# MSP430FR5739 register map
File version: 1.1
CPU: msp430
Registers are 16-bit, access not given, reset 0x0 unless marked. A register's access mark holds for its fields unless they carry their own. Offsets are from the block's base; [hi:lo] are bit positions; {n}, {i} and the like mark numbered series.

## SFR__Special_Function_Registers
Base 0x00000000
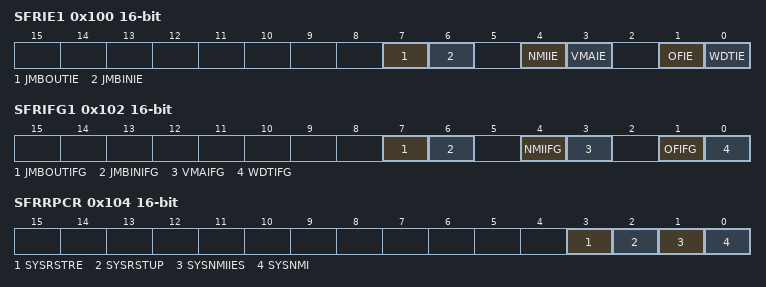
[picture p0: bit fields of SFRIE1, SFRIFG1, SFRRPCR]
0x100 SFRIE1 — Interrupt Enable 1
  [7] JMBOUTIE — [7:7] JTAG Mail Box output Interrupt Enable
  [6] JMBINIE — [6:6] JTAG Mail Box input Interrupt Enable
  [4] NMIIE — [4:4] NMI Interrupt Enable
  [3] VMAIE — [3:3] Vacant Memory Interrupt Enable
  [1] OFIE — [1:1] Osc Fault Enable
  [0] WDTIE — [0:0] WDT Interrupt Enable
0x102 SFRIFG1 — Interrupt Flag 1
  [7] JMBOUTIFG — [7:7] JTAG Mail Box output Interrupt Flag
  [6] JMBINIFG — [6:6] JTAG Mail Box input Interrupt Flag
  [4] NMIIFG — [4:4] NMI Interrupt Flag
  [3] VMAIFG — [3:3] Vacant Memory Interrupt Flag
  [1] OFIFG — [1:1] Osc Fault Flag
  [0] WDTIFG — [0:0] WDT Interrupt Flag
0x104 SFRRPCR — RESET Pin Control Register
  [3] SYSRSTRE — [3:3] RESET Pin Resistor enable
  [2] SYSRSTUP — [2:2] RESET Pin pull down/up select
  [1] SYSNMIIES — [1:1] NMI edge select
  [0] SYSNMI — [0:0] NMI select

## SYS__System_Module
Base 0x00000000
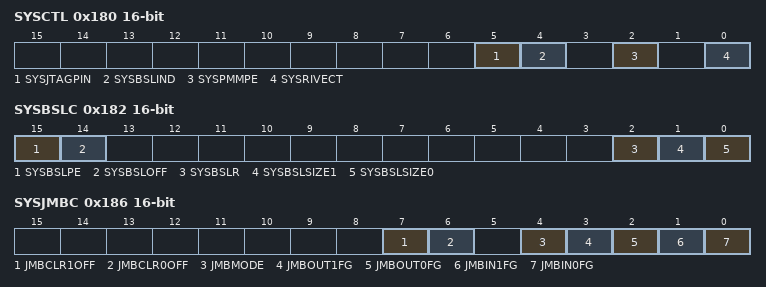
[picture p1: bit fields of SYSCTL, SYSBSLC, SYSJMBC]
0x180 SYSCTL — System control
  [5] SYSJTAGPIN — [5:5] SYS - Dedicated JTAG pins enabled
  [4] SYSBSLIND — [4:4] SYS - TCK/RST indication detected
  [2] SYSPMMPE — [2:2] SYS - PMM access protect
  [0] SYSRIVECT — [0:0] SYS - RAM based interrupt vectors
0x182 SYSBSLC — Boot strap configuration area
  [15] SYSBSLPE — [15:15] SYS - BSL Memory protection enabled
  [14] SYSBSLOFF — [14:14] SYS - BSL Memory disabled
  [2] SYSBSLR — [2:2] SYS - RAM assigned to BSL
  [1] SYSBSLSIZE1 — [1:1] SYS - BSL Protection Size 1
  [0] SYSBSLSIZE0 — [0:0] SYS - BSL Protection Size 0
0x186 SYSJMBC — JTAG mailbox control
  [7] JMBCLR1OFF — [7:7] SYS - Incoming JTAG Mailbox 1 Flag auto-clear disalbe
  [6] JMBCLR0OFF — [6:6] SYS - Incoming JTAG Mailbox 0 Flag auto-clear disalbe
  [4] JMBMODE — [4:4] SYS - JMB 16/32 Bit Mode
  [3] JMBOUT1FG — [3:3] SYS - Outgoing JTAG Mailbox 1 Flag
  [2] JMBOUT0FG — [2:2] SYS - Outgoing JTAG Mailbox 0 Flag
  [1] JMBIN1FG — [1:1] SYS - Incoming JTAG Mailbox 1 Flag
  [0] JMBIN0FG — [0:0] SYS - Incoming JTAG Mailbox 0 Flag
0x188 SYSJMBI0 — JTAG mailbox input 0
0x18A SYSJMBI1 — JTAG mailbox input 1
0x18C SYSJMBO0 — JTAG mailbox output 0
0x18E SYSJMBO1 — JTAG mailbox output 1
0x198 SYSBERRIV — Bus Error vector generator
0x19A SYSUNIV — User NMI vector generator
0x19C SYSSNIV — System NMI vector generator
0x19E SYSRSTIV — Reset vector generator

## Timer0_A3
Base 0x00000000
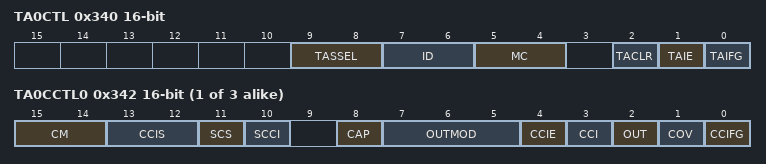
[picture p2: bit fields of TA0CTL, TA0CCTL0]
0x340 TA0CTL — Timer0_A3 Control
  [9:8] TASSEL — [9:8] Timer A clock source select 1
    0=Timer A clock source select: 0 - TACLK; 1=Timer A clock source select: 1 - ACLK; 2=Timer A clock source select: 2 - SMCLK; 3=Timer A clock source select: 3 - INCLK
  [7:6] ID — [7:6] Timer A clock input divider 1
    0=Timer A input divider: 0 - /1; 1=Timer A input divider: 1 - /2; 2=Timer A input divider: 2 - /4; 3=Timer A input divider: 3 - /8
  [5:4] MC — [5:4] Timer A mode control 1
    0=Timer A mode control: 0 - Stop; 1=Timer A mode control: 1 - Up to CCR0; 2=Timer A mode control: 2 - Continuous up; 3=Timer A mode control: 3 - Up/Down
  [2] TACLR — [2:2] Timer A counter clear
  [1] TAIE — [1:1] Timer A counter interrupt enable
  [0] TAIFG — [0:0] Timer A counter interrupt flag
{0x342+2i} TA0CCTL{i} (i=0..2) — Timer0_A3 Capture/Compare Control {i}
  [15:14] CM — [15:14] Capture mode 1
    0=Capture mode: 0 - disabled; 1=Capture mode: 1 - pos. edge; 2=Capture mode: 1 - neg. edge; 3=Capture mode: 1 - both edges
  [13:12] CCIS — [13:12] Capture input select 1
    0=Capture input select: 0 - CCIxA; 1=Capture input select: 1 - CCIxB; 2=Capture input select: 2 - GND; 3=Capture input select: 3 - Vcc
  [11] SCS — [11:11] Capture sychronize
  [10] SCCI — [10:10] Latched capture signal (read)
  [8] CAP — [8:8] Capture mode: 1 /Compare mode : 0
  [7:5] OUTMOD — [7:5] Output mode 2
    0=PWM output mode: 0 - output only; 1=PWM output mode: 1 - set; 2=PWM output mode: 2 - PWM toggle/reset; 3=PWM output mode: 3 - PWM set/reset; 4=PWM output mode: 4 - toggle; 5=PWM output mode: 5 - Reset; 6=PWM output mode: 6 - PWM toggle/set; 7=PWM output mode: 7 - PWM reset/set
  [4] CCIE — [4:4] Capture/compare interrupt enable
  [3] CCI — [3:3] Capture input signal (read)
  [2] OUT — [2:2] PWM Output signal if output mode 0
  [1] COV — [1:1] Capture/compare overflow flag
  [0] CCIFG — [0:0] Capture/compare interrupt flag
0x350 TA0R — Timer0_A3
{0x352+2i} TA0CCR{i} (i=0..2) — Timer0_A3 Capture/Compare {i}
0x360 TA0EX0 — Timer0_A3 Expansion Register 0
  [2:0] TAIDEX — [2:0] Timer A Input divider expansion Bit: 0
    {v}=Timer A Input divider expansion : /{v+1} (v=0..7)
0x36E TA0IV — Timer0_A3 Interrupt Vector Word
